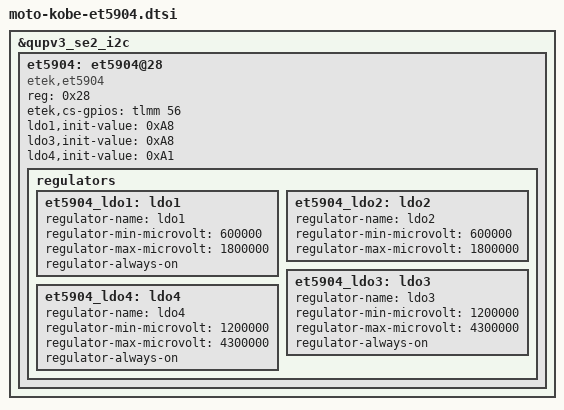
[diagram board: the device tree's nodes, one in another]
&qupv3_se2_i2c {
	status = "ok";
	et5904: et5904@28 {
		compatible = "etek,et5904";
		reg = <0x28>;

		etek,cs-gpios = <&tlmm 56 0>;
		ldo1,init-value = <0xA8>;
		ldo3,init-value = <0xA8>;
		ldo4,init-value = <0xA1>;

		regulators {
			et5904_ldo1: ldo1 {
				regulator-name = "ldo1";
				regulator-min-microvolt = <600000>;
				regulator-max-microvolt = <1800000>;
				regulator-always-on;
			};

			et5904_ldo2: ldo2 {
				regulator-name = "ldo2";
				regulator-min-microvolt = <600000>;
				regulator-max-microvolt = <1800000>;

			};

			et5904_ldo3: ldo3 {
				regulator-name = "ldo3";
				regulator-min-microvolt = <1200000>;
				regulator-max-microvolt = <4300000>;
				regulator-always-on;
			};

			et5904_ldo4: ldo4 {
				regulator-name = "ldo4";
				regulator-min-microvolt = <1200000>;
				regulator-max-microvolt = <4300000>;
				regulator-always-on;
			};
		};
	};
};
